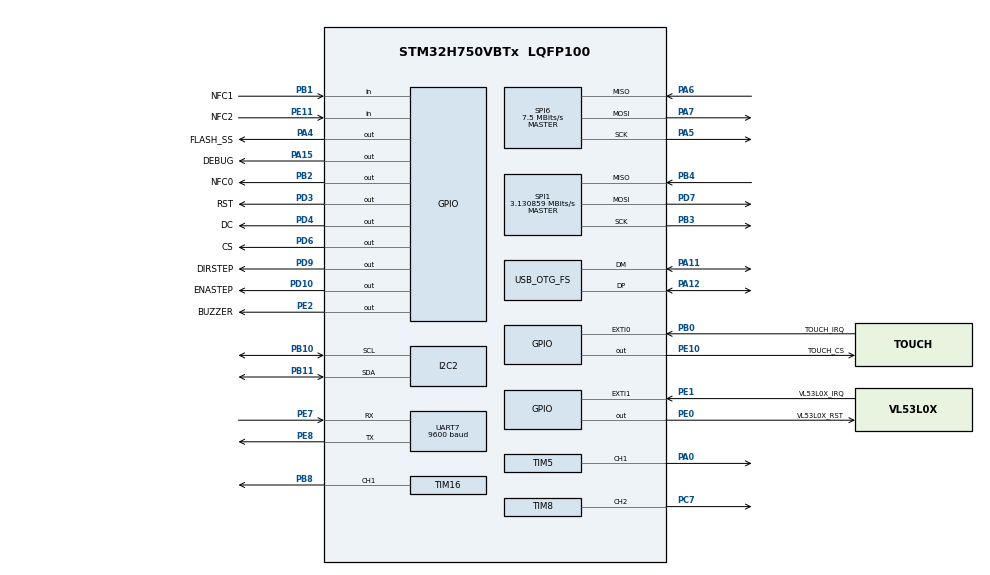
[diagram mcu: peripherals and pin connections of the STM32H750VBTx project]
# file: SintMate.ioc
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Dma.Request0=TIM16_CH1
Dma.Request1=SPI1_TX
Dma.Request2=TIM8_CH2
Dma.SPI1_TX.1.Direction=DMA_MEMORY_TO_PERIPH
Dma.SPI1_TX.1.EventEnable=DISABLE
Dma.SPI1_TX.1.FIFOMode=DMA_FIFOMODE_DISABLE
Dma.SPI1_TX.1.Instance=DMA1_Stream0
Dma.SPI1_TX.1.MemDataAlignment=DMA_MDATAALIGN_BYTE
Dma.SPI1_TX.1.MemInc=DMA_MINC_ENABLE
Dma.SPI1_TX.1.Mode=DMA_NORMAL
Dma.SPI1_TX.1.PeriphDataAlignment=DMA_PDATAALIGN_BYTE
Dma.SPI1_TX.1.PeriphInc=DMA_PINC_DISABLE
Dma.SPI1_TX.1.Polarity=HAL_DMAMUX_REQ_GEN_RISING
Dma.SPI1_TX.1.Priority=DMA_PRIORITY_LOW
Dma.SPI1_TX.1.RequestNumber=1
Dma.SPI1_TX.1.SignalID=NONE
Dma.SPI1_TX.1.SyncEnable=DISABLE
Dma.SPI1_TX.1.SyncPolarity=HAL_DMAMUX_SYNC_NO_EVENT
Dma.SPI1_TX.1.SyncRequestNumber=1
Dma.SPI1_TX.1.SyncSignalID=NONE
Dma.TIM16_CH1.0.Direction=DMA_MEMORY_TO_PERIPH
Dma.TIM16_CH1.0.EventEnable=DISABLE
Dma.TIM16_CH1.0.FIFOMode=DMA_FIFOMODE_DISABLE
Dma.TIM16_CH1.0.Instance=DMA1_Stream1
Dma.TIM16_CH1.0.MemDataAlignment=DMA_MDATAALIGN_HALFWORD
Dma.TIM16_CH1.0.MemInc=DMA_MINC_ENABLE
Dma.TIM16_CH1.0.Mode=DMA_NORMAL
Dma.TIM16_CH1.0.PeriphDataAlignment=DMA_PDATAALIGN_HALFWORD
Dma.TIM16_CH1.0.PeriphInc=DMA_PINC_DISABLE
Dma.TIM16_CH1.0.Polarity=HAL_DMAMUX_REQ_GEN_RISING
Dma.TIM16_CH1.0.Priority=DMA_PRIORITY_LOW
Dma.TIM16_CH1.0.RequestNumber=1
Dma.TIM16_CH1.0.SignalID=NONE
Dma.TIM16_CH1.0.SyncEnable=DISABLE
Dma.TIM16_CH1.0.SyncPolarity=HAL_DMAMUX_SYNC_NO_EVENT
Dma.TIM16_CH1.0.SyncRequestNumber=1
Dma.TIM16_CH1.0.SyncSignalID=NONE
Dma.TIM8_CH2.2.Direction=DMA_MEMORY_TO_PERIPH
Dma.TIM8_CH2.2.EventEnable=DISABLE
Dma.TIM8_CH2.2.FIFOMode=DMA_FIFOMODE_DISABLE
Dma.TIM8_CH2.2.Instance=DMA1_Stream2
Dma.TIM8_CH2.2.MemDataAlignment=DMA_MDATAALIGN_HALFWORD
Dma.TIM8_CH2.2.MemInc=DMA_MINC_ENABLE
Dma.TIM8_CH2.2.Mode=DMA_NORMAL
Dma.TIM8_CH2.2.PeriphDataAlignment=DMA_PDATAALIGN_HALFWORD
Dma.TIM8_CH2.2.PeriphInc=DMA_PINC_DISABLE
Dma.TIM8_CH2.2.Polarity=HAL_DMAMUX_REQ_GEN_RISING
Dma.TIM8_CH2.2.Priority=DMA_PRIORITY_LOW
Dma.TIM8_CH2.2.RequestNumber=1
Dma.TIM8_CH2.2.SignalID=NONE
Dma.TIM8_CH2.2.SyncEnable=DISABLE
Dma.TIM8_CH2.2.SyncPolarity=HAL_DMAMUX_SYNC_NO_EVENT
Dma.TIM8_CH2.2.SyncRequestNumber=1
Dma.TIM8_CH2.2.SyncSignalID=NONE
I2C2.Speed=100
I2C2.Timing=0x00000E14
Mcu.Family=STM32H7
Mcu.Name=STM32H750VBTx
Mcu.Package=LQFP100
NVIC.DMA1_Stream0_IRQn=true\:0\:0\:false\:false\:true\:false\:true
NVIC.DMA1_Stream1_IRQn=true\:0\:0\:false\:false\:true\:false\:true
NVIC.DMA1_Stream2_IRQn=true\:0\:0\:false\:false\:true\:false\:true
NVIC.EXTI0_IRQn=true\:0\:0\:false\:false\:true\:true\:true
NVIC.EXTI1_IRQn=true\:0\:0\:false\:false\:true\:true\:true
NVIC.OTG_FS_IRQn=true\:0\:0\:false\:false\:true\:false\:true
NVIC.PriorityGroup=NVIC_PRIORITYGROUP_4
NVIC.SPI1_IRQn=true\:0\:0\:false\:false\:true\:true\:true
NVIC.TIM6_DAC_IRQn=true\:0\:0\:false\:false\:true\:true\:true
NVIC.TIM7_IRQn=true\:0\:0\:false\:false\:true\:true\:true
NVIC.UART7_IRQn=true\:0\:0\:false\:false\:true\:true\:true
PA0.Signal=S_TIM5_CH1
PA11.Mode=Device_Only
PA11.Signal=USB_OTG_FS_DM
PA12.Mode=Device_Only
PA12.Signal=USB_OTG_FS_DP
PA13\ (JTMS/SWDIO).Mode=Serial_Wire
PA13\ (JTMS/SWDIO).Signal=DEBUG_JTMS-SWDIO
PA14\ (JTCK/SWCLK).Mode=Serial_Wire
PA14\ (JTCK/SWCLK).Signal=DEBUG_JTCK-SWCLK
PA15\ (JTDI).GPIO_Label=DEBUG
PA15\ (JTDI).Signal=GPIO_Output
PA4.GPIO_Label=FLASH_SS
PA4.PinState=GPIO_PIN_SET
PA4.Signal=GPIO_Output
PA5.Mode=Full_Duplex_Master
PA5.Signal=SPI6_SCK
PA6.Mode=Full_Duplex_Master
PA6.Signal=SPI6_MISO
PA7.Mode=Full_Duplex_Master
PA7.Signal=SPI6_MOSI
PB0.GPIO_Label=TOUCH_IRQ
PB0.GPIO_ModeDefaultEXTI=GPIO_MODE_IT_FALLING
PB0.GPIO_PuPd=GPIO_PULLUP
PB0.Signal=GPXTI0
PB1.GPIO_Label=NFC1
PB1.GPIO_PuPd=GPIO_PULLUP
PB1.Signal=GPIO_Input
PB10.Mode=I2C
PB10.Signal=I2C2_SCL
PB11.Mode=I2C
PB11.Signal=I2C2_SDA
PB2.GPIO_Label=NFC0
PB2.Signal=GPIO_Output
PB3\ (JTDO/TRACESWO).Mode=Full_Duplex_Master
PB3\ (JTDO/TRACESWO).Signal=SPI1_SCK
PB4\ (NJTRST).Mode=Full_Duplex_Master
PB4\ (NJTRST).Signal=SPI1_MISO
PB8.Signal=S_TIM16_CH1
PC7.Signal=S_TIM8_CH2
PD10.GPIO_Label=ENASTEP
PD10.GPIO_ModeDefaultOutputPP=GPIO_MODE_OUTPUT_OD
PD10.GPIO_PuPd=GPIO_PULLUP
PD10.PinState=GPIO_PIN_SET
PD10.Signal=GPIO_Output
PD3.GPIO_Label=RST
PD3.Signal=GPIO_Output
PD4.GPIO_Label=DC
PD4.Signal=GPIO_Output
PD6.GPIO_Label=CS
PD6.PinState=GPIO_PIN_SET
PD6.Signal=GPIO_Output
PD7.Mode=Full_Duplex_Master
PD7.Signal=SPI1_MOSI
PD9.GPIO_Label=DIRSTEP
PD9.Signal=GPIO_Output
PE0.GPIO_Label=VL53L0X_RST
PE0.Signal=GPIO_Output
PE1.GPIO_Label=VL53L0X_IRQ
PE1.GPIO_ModeDefaultEXTI=GPIO_MODE_IT_FALLING
PE1.GPIO_PuPd=GPIO_PULLUP
PE1.Signal=GPXTI1
PE10.GPIO_Label=TOUCH_CS
PE10.PinState=GPIO_PIN_SET
PE10.Signal=GPIO_Output
PE11.GPIO_Label=NFC2
PE11.GPIO_PuPd=GPIO_PULLUP
PE11.Signal=GPIO_Input
PE2.GPIO_Label=BUZZER
PE2.PinState=GPIO_PIN_SET
PE2.Signal=GPIO_Output
PE7.Mode=Asynchronous
PE7.Signal=UART7_RX
PE8.Mode=Asynchronous
PE8.Signal=UART7_TX
ProjectManager.HeapSize=0x200
ProjectManager.StackSize=0x400
ProjectManager.TargetToolchain=STM32CubeIDE
RCC.ADCFreq_Value=200375000
RCC.APB1Freq_Value=120000000
RCC.APB2Freq_Value=120000000
RCC.APB3Freq_Value=120000000
RCC.APB4Freq_Value=120000000
RCC.CortexFreq_Value=480000000
RCC.D1PPRE=RCC_APB3_DIV2
RCC.D2PPRE1=RCC_APB1_DIV2
RCC.D2PPRE2=RCC_APB2_DIV2
RCC.D3PPRE=RCC_APB4_DIV2
RCC.DIVM1=4
RCC.DIVN1=60
RCC.DIVN2=200
RCC.DIVN3=96
RCC.DIVP3=4
RCC.DIVQ3=4
RCC.DIVR3=1
RCC.HCLKFreq_Value=240000000
RCC.HPRE=RCC_HCLK_DIV2
RCC.HSE_VALUE=24000000
RCC.I2C123CLockSelection=RCC_I2C123CLKSOURCE_CSI
RCC.PLL2FRACN=3072
RCC.PLL3FRACN=3072
RCC.PLLFRACN=0
RCC.SPI123CLockSelection=RCC_SPI123CLKSOURCE_PLL2
RCC.SYSCLKFreq_VALUE=480000000
RCC.SYSCLKSource=RCC_SYSCLKSOURCE_PLLCLK
RCC.USBCLockSelection=RCC_USBCLKSOURCE_HSI48
RCC.USBFreq_Value=48000000
SH.S_TIM16_CH1.0=TIM16_CH1,Output Compare1 CH1
SH.S_TIM5_CH1.0=TIM5_CH1,PWM Generation1 CH1
SH.S_TIM8_CH2.0=TIM8_CH2,PWM Generation2 CH2
SPI1.BaudRatePrescaler=SPI_BAUDRATEPRESCALER_64
SPI1.CalculateBaudRate=3.130859 MBits/s
SPI1.DataSize=SPI_DATASIZE_8BIT
SPI1.Direction=SPI_DIRECTION_2LINES
SPI1.Mode=SPI_MODE_MASTER
SPI1.VirtualType=VM_MASTER
SPI6.BaudRatePrescaler=SPI_BAUDRATEPRESCALER_16
SPI6.CalculateBaudRate=7.5 MBits/s
SPI6.DataSize=SPI_DATASIZE_8BIT
SPI6.Direction=SPI_DIRECTION_2LINES
SPI6.Mode=SPI_MODE_MASTER
SPI6.VirtualType=VM_MASTER
TIM16.AutoReloadPreload=TIM_AUTORELOAD_PRELOAD_ENABLE
TIM16.Channel=TIM_CHANNEL_1
TIM16.OCMode_1=TIM_OCMODE_TOGGLE
TIM16.Period=2002
TIM16.Prescaler=424
TIM16.Pulse=200
TIM5.Channel-PWM\ Generation1\ CH1=TIM_CHANNEL_1
TIM5.Period=1000
TIM5.Prescaler=240
TIM5.Pulse-PWM\ Generation1\ CH1=500
TIM6.Period=1587
TIM6.Prescaler=2400
TIM7.Period=10000
TIM7.Prescaler=2400
TIM8.AutoReloadPreload=TIM_AUTORELOAD_PRELOAD_ENABLE
TIM8.Channel-PWM\ Generation2\ CH2=TIM_CHANNEL_2
TIM8.Period=90
TIM8.Prescaler=1
UART7.BaudRate=9600
USB_DEVICE.CLASS_NAME_FS=CDC
USB_DEVICE.VirtualMode-CDC_FS=Cdc
USB_DEVICE.VirtualModeFS=Cdc_FS
USB_OTG_FS.VirtualMode=Device_Only
VP_TIM16_VS_ClockSourceINT.Mode=Enable_Timer
VP_TIM6_VS_ClockSourceINT.Mode=Enable_Timer
VP_TIM7_VS_ClockSourceINT.Mode=Enable_Timer
VP_USB_DEVICE_VS_USB_DEVICE_CDC_FS.Mode=CDC_FS
board=custom

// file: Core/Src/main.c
/* USER CODE BEGIN Header */
/**
  ******************************************************************************
  * @file           : main.c
  * @brief          : Main program body
  ******************************************************************************
  * @attention
  *
  * <h2><center>&copy; Copyright (c) 2021 STMicroelectronics.
  * All rights reserved.</center></h2>
  *
  * This software component is licensed by ST under BSD 3-Clause license,
  * the "License"; You may not use this file except in compliance with the
  * License. You may obtain a copy of the License at:
  *                        opensource.org/licenses/BSD-3-Clause
  *
  ******************************************************************************
  */
/* USER CODE END Header */
#include "main.h"
#include "usb_device.h"

I2C_HandleTypeDef hi2c2;

SPI_HandleTypeDef hspi1;
SPI_HandleTypeDef hspi6;
DMA_HandleTypeDef hdma_spi1_tx;

TIM_HandleTypeDef htim5;
TIM_HandleTypeDef htim6;
TIM_HandleTypeDef htim7;
TIM_HandleTypeDef htim8;
TIM_HandleTypeDef htim16;
DMA_HandleTypeDef hdma_tim8_ch2;
DMA_HandleTypeDef hdma_tim16_ch1;

UART_HandleTypeDef huart7;

void SystemClock_Config(void);
static void MX_GPIO_Init(void);
static void MX_DMA_Init(void);
static void MX_TIM16_Init(void);
static void MX_I2C2_Init(void);
static void MX_SPI1_Init(void);
static void MX_SPI6_Init(void);
static void MX_TIM5_Init(void);
static void MX_TIM7_Init(void);
static void MX_TIM8_Init(void);
static void MX_UART7_Init(void);
static void MX_TIM6_Init(void);

int main(void)
{

  /* MCU Configuration--------------------------------------------------------*/

  /* Reset of all peripherals, Initializes the Flash interface and the Systick. */
  HAL_Init();

  /* Configure the system clock */
  SystemClock_Config();

  /* Initialize all configured peripherals */
  MX_GPIO_Init();
  MX_DMA_Init();
  MX_TIM16_Init();
  MX_I2C2_Init();
  MX_SPI1_Init();
  MX_SPI6_Init();
  MX_TIM5_Init();
  MX_TIM7_Init();
  MX_USB_DEVICE_Init();
  MX_TIM8_Init();
  MX_UART7_Init();
  MX_TIM6_Init();
  /* USER CODE BEGIN 2 */
  Init_SintMate();

  /* USER CODE END 2 */

  /* Infinite loop */
  /* USER CODE BEGIN WHILE */
  while (1)
  {
	  SintMateLoop();

    /* USER CODE END WHILE */

  }
}

void SystemClock_Config(void)
{
  RCC_OscInitTypeDef RCC_OscInitStruct = {0};
  RCC_ClkInitTypeDef RCC_ClkInitStruct = {0};
  RCC_PeriphCLKInitTypeDef PeriphClkInitStruct = {0};

  /** Supply configuration update enable
  */
  HAL_PWREx_ConfigSupply(PWR_LDO_SUPPLY);
  /** Configure the main internal regulator output voltage
  */
  __HAL_PWR_VOLTAGESCALING_CONFIG(PWR_REGULATOR_VOLTAGE_SCALE0);

  while(!__HAL_PWR_GET_FLAG(PWR_FLAG_VOSRDY)) {}
  /** Macro to configure the PLL clock source
  */
  __HAL_RCC_PLL_PLLSOURCE_CONFIG(RCC_PLLSOURCE_HSI);
  /** Initializes the RCC Oscillators according to the specified parameters
  * in the RCC_OscInitTypeDef structure.
  */
  RCC_OscInitStruct.OscillatorType = RCC_OSCILLATORTYPE_HSI48|RCC_OSCILLATORTYPE_CSI
                              |RCC_OSCILLATORTYPE_HSI;
  RCC_OscInitStruct.HSIState = RCC_HSI_DIV1;
  RCC_OscInitStruct.HSICalibrationValue = RCC_HSICALIBRATION_DEFAULT;
  RCC_OscInitStruct.HSI48State = RCC_HSI48_ON;
  RCC_OscInitStruct.CSIState = RCC_CSI_ON;
  RCC_OscInitStruct.CSICalibrationValue = 16;
  RCC_OscInitStruct.PLL.PLLState = RCC_PLL_ON;
  RCC_OscInitStruct.PLL.PLLSource = RCC_PLLSOURCE_HSI;
  RCC_OscInitStruct.PLL.PLLM = 4;
  RCC_OscInitStruct.PLL.PLLN = 60;
  RCC_OscInitStruct.PLL.PLLP = 2;
  RCC_OscInitStruct.PLL.PLLQ = 2;
  RCC_OscInitStruct.PLL.PLLR = 2;
  RCC_OscInitStruct.PLL.PLLRGE = RCC_PLL1VCIRANGE_3;
  RCC_OscInitStruct.PLL.PLLVCOSEL = RCC_PLL1VCOWIDE;
  RCC_OscInitStruct.PLL.PLLFRACN = 0;
  if (HAL_RCC_OscConfig(&RCC_OscInitStruct) != HAL_OK)
  {
    Error_Handler();
  }
  /** Initializes the CPU, AHB and APB buses clocks
  */
  RCC_ClkInitStruct.ClockType = RCC_CLOCKTYPE_HCLK|RCC_CLOCKTYPE_SYSCLK
                              |RCC_CLOCKTYPE_PCLK1|RCC_CLOCKTYPE_PCLK2
                              |RCC_CLOCKTYPE_D3PCLK1|RCC_CLOCKTYPE_D1PCLK1;
  RCC_ClkInitStruct.SYSCLKSource = RCC_SYSCLKSOURCE_PLLCLK;
  RCC_ClkInitStruct.SYSCLKDivider = RCC_SYSCLK_DIV1;
  RCC_ClkInitStruct.AHBCLKDivider = RCC_HCLK_DIV2;
  RCC_ClkInitStruct.APB3CLKDivider = RCC_APB3_DIV2;
  RCC_ClkInitStruct.APB1CLKDivider = RCC_APB1_DIV2;
  RCC_ClkInitStruct.APB2CLKDivider = RCC_APB2_DIV2;
  RCC_ClkInitStruct.APB4CLKDivider = RCC_APB4_DIV2;

  if (HAL_RCC_ClockConfig(&RCC_ClkInitStruct, FLASH_LATENCY_4) != HAL_OK)
  {
    Error_Handler();
  }
  PeriphClkInitStruct.PeriphClockSelection = RCC_PERIPHCLK_UART7|RCC_PERIPHCLK_SPI1
                              |RCC_PERIPHCLK_I2C2|RCC_PERIPHCLK_SPI6
                              |RCC_PERIPHCLK_USB;
  PeriphClkInitStruct.PLL2.PLL2M = 32;
  PeriphClkInitStruct.PLL2.PLL2N = 200;
  PeriphClkInitStruct.PLL2.PLL2P = 2;
  PeriphClkInitStruct.PLL2.PLL2Q = 2;
  PeriphClkInitStruct.PLL2.PLL2R = 2;
  PeriphClkInitStruct.PLL2.PLL2RGE = RCC_PLL2VCIRANGE_1;
  PeriphClkInitStruct.PLL2.PLL2VCOSEL = RCC_PLL2VCOWIDE;
  PeriphClkInitStruct.PLL2.PLL2FRACN = 3072;
  PeriphClkInitStruct.Spi123ClockSelection = RCC_SPI123CLKSOURCE_PLL2;
  PeriphClkInitStruct.Usart234578ClockSelection = RCC_USART234578CLKSOURCE_D2PCLK1;
  PeriphClkInitStruct.I2c123ClockSelection = RCC_I2C123CLKSOURCE_CSI;
  PeriphClkInitStruct.UsbClockSelection = RCC_USBCLKSOURCE_HSI48;
  PeriphClkInitStruct.Spi6ClockSelection = RCC_SPI6CLKSOURCE_D3PCLK1;
  if (HAL_RCCEx_PeriphCLKConfig(&PeriphClkInitStruct) != HAL_OK)
  {
    Error_Handler();
  }
  /** Enable USB Voltage detector
  */
  HAL_PWREx_EnableUSBVoltageDetector();
}

static void MX_I2C2_Init(void)
{

  hi2c2.Instance = I2C2;
  hi2c2.Init.Timing = 0x00000E14;
  hi2c2.Init.OwnAddress1 = 0;
  hi2c2.Init.AddressingMode = I2C_ADDRESSINGMODE_7BIT;
  hi2c2.Init.DualAddressMode = I2C_DUALADDRESS_DISABLE;
  hi2c2.Init.OwnAddress2 = 0;
  hi2c2.Init.OwnAddress2Masks = I2C_OA2_NOMASK;
  hi2c2.Init.GeneralCallMode = I2C_GENERALCALL_DISABLE;
  hi2c2.Init.NoStretchMode = I2C_NOSTRETCH_DISABLE;
  if (HAL_I2C_Init(&hi2c2) != HAL_OK)
  {
    Error_Handler();
  }
  /** Configure Analogue filter
  */
  if (HAL_I2CEx_ConfigAnalogFilter(&hi2c2, I2C_ANALOGFILTER_ENABLE) != HAL_OK)
  {
    Error_Handler();
  }
  /** Configure Digital filter
  */
  if (HAL_I2CEx_ConfigDigitalFilter(&hi2c2, 0) != HAL_OK)
  {
    Error_Handler();
  }

}

static void MX_SPI1_Init(void)
{

  /* SPI1 parameter configuration*/
  hspi1.Instance = SPI1;
  hspi1.Init.Mode = SPI_MODE_MASTER;
  hspi1.Init.Direction = SPI_DIRECTION_2LINES;
  hspi1.Init.DataSize = SPI_DATASIZE_8BIT;
  hspi1.Init.CLKPolarity = SPI_POLARITY_LOW;
  hspi1.Init.CLKPhase = SPI_PHASE_1EDGE;
  hspi1.Init.NSS = SPI_NSS_SOFT;
  hspi1.Init.BaudRatePrescaler = SPI_BAUDRATEPRESCALER_64;
  hspi1.Init.FirstBit = SPI_FIRSTBIT_MSB;
  hspi1.Init.TIMode = SPI_TIMODE_DISABLE;
  hspi1.Init.CRCCalculation = SPI_CRCCALCULATION_DISABLE;
  hspi1.Init.CRCPolynomial = 0x0;
  hspi1.Init.NSSPMode = SPI_NSS_PULSE_ENABLE;
  hspi1.Init.NSSPolarity = SPI_NSS_POLARITY_LOW;
  hspi1.Init.FifoThreshold = SPI_FIFO_THRESHOLD_01DATA;
  hspi1.Init.TxCRCInitializationPattern = SPI_CRC_INITIALIZATION_ALL_ZERO_PATTERN;
  hspi1.Init.RxCRCInitializationPattern = SPI_CRC_INITIALIZATION_ALL_ZERO_PATTERN;
  hspi1.Init.MasterSSIdleness = SPI_MASTER_SS_IDLENESS_00CYCLE;
  hspi1.Init.MasterInterDataIdleness = SPI_MASTER_INTERDATA_IDLENESS_00CYCLE;
  hspi1.Init.MasterReceiverAutoSusp = SPI_MASTER_RX_AUTOSUSP_DISABLE;
  hspi1.Init.MasterKeepIOState = SPI_MASTER_KEEP_IO_STATE_DISABLE;
  hspi1.Init.IOSwap = SPI_IO_SWAP_DISABLE;
  if (HAL_SPI_Init(&hspi1) != HAL_OK)
  {
    Error_Handler();
  }

}

static void MX_SPI6_Init(void)
{

  /* SPI6 parameter configuration*/
  hspi6.Instance = SPI6;
  hspi6.Init.Mode = SPI_MODE_MASTER;
  hspi6.Init.Direction = SPI_DIRECTION_2LINES;
  hspi6.Init.DataSize = SPI_DATASIZE_8BIT;
  hspi6.Init.CLKPolarity = SPI_POLARITY_LOW;
  hspi6.Init.CLKPhase = SPI_PHASE_1EDGE;
  hspi6.Init.NSS = SPI_NSS_SOFT;
  hspi6.Init.BaudRatePrescaler = SPI_BAUDRATEPRESCALER_16;
  hspi6.Init.FirstBit = SPI_FIRSTBIT_MSB;
  hspi6.Init.TIMode = SPI_TIMODE_DISABLE;
  hspi6.Init.CRCCalculation = SPI_CRCCALCULATION_DISABLE;
  hspi6.Init.CRCPolynomial = 0x0;
  hspi6.Init.NSSPMode = SPI_NSS_PULSE_ENABLE;
  hspi6.Init.NSSPolarity = SPI_NSS_POLARITY_LOW;
  hspi6.Init.FifoThreshold = SPI_FIFO_THRESHOLD_01DATA;
  hspi6.Init.TxCRCInitializationPattern = SPI_CRC_INITIALIZATION_ALL_ZERO_PATTERN;
  hspi6.Init.RxCRCInitializationPattern = SPI_CRC_INITIALIZATION_ALL_ZERO_PATTERN;
  hspi6.Init.MasterSSIdleness = SPI_MASTER_SS_IDLENESS_00CYCLE;
  hspi6.Init.MasterInterDataIdleness = SPI_MASTER_INTERDATA_IDLENESS_00CYCLE;
  hspi6.Init.MasterReceiverAutoSusp = SPI_MASTER_RX_AUTOSUSP_DISABLE;
  hspi6.Init.MasterKeepIOState = SPI_MASTER_KEEP_IO_STATE_DISABLE;
  hspi6.Init.IOSwap = SPI_IO_SWAP_DISABLE;
  if (HAL_SPI_Init(&hspi6) != HAL_OK)
  {
    Error_Handler();
  }

}

static void MX_TIM5_Init(void)
{

  TIM_MasterConfigTypeDef sMasterConfig = {0};
  TIM_OC_InitTypeDef sConfigOC = {0};

  htim5.Instance = TIM5;
  htim5.Init.Prescaler = 240;
  htim5.Init.CounterMode = TIM_COUNTERMODE_UP;
  htim5.Init.Period = 1000;
  htim5.Init.ClockDivision = TIM_CLOCKDIVISION_DIV1;
  htim5.Init.AutoReloadPreload = TIM_AUTORELOAD_PRELOAD_DISABLE;
  if (HAL_TIM_PWM_Init(&htim5) != HAL_OK)
  {
    Error_Handler();
  }
  sMasterConfig.MasterOutputTrigger = TIM_TRGO_RESET;
  sMasterConfig.MasterSlaveMode = TIM_MASTERSLAVEMODE_DISABLE;
  if (HAL_TIMEx_MasterConfigSynchronization(&htim5, &sMasterConfig) != HAL_OK)
  {
    Error_Handler();
  }
  sConfigOC.OCMode = TIM_OCMODE_PWM1;
  sConfigOC.Pulse = 500;
  sConfigOC.OCPolarity = TIM_OCPOLARITY_HIGH;
  sConfigOC.OCFastMode = TIM_OCFAST_DISABLE;
  if (HAL_TIM_PWM_ConfigChannel(&htim5, &sConfigOC, TIM_CHANNEL_1) != HAL_OK)
  {
    Error_Handler();
  }
  HAL_TIM_MspPostInit(&htim5);

}

static void MX_TIM6_Init(void)
{

  TIM_MasterConfigTypeDef sMasterConfig = {0};

  htim6.Instance = TIM6;
  htim6.Init.Prescaler = 2400;
  htim6.Init.CounterMode = TIM_COUNTERMODE_UP;
  htim6.Init.Period = 1587;
  htim6.Init.AutoReloadPreload = TIM_AUTORELOAD_PRELOAD_DISABLE;
  if (HAL_TIM_Base_Init(&htim6) != HAL_OK)
  {
    Error_Handler();
  }
  sMasterConfig.MasterOutputTrigger = TIM_TRGO_RESET;
  sMasterConfig.MasterSlaveMode = TIM_MASTERSLAVEMODE_DISABLE;
  if (HAL_TIMEx_MasterConfigSynchronization(&htim6, &sMasterConfig) != HAL_OK)
  {
    Error_Handler();
  }

}

static void MX_TIM7_Init(void)
{

  TIM_MasterConfigTypeDef sMasterConfig = {0};

  htim7.Instance = TIM7;
  htim7.Init.Prescaler = 2400;
  htim7.Init.CounterMode = TIM_COUNTERMODE_UP;
  htim7.Init.Period = 10000;
  htim7.Init.AutoReloadPreload = TIM_AUTORELOAD_PRELOAD_DISABLE;
  if (HAL_TIM_Base_Init(&htim7) != HAL_OK)
  {
    Error_Handler();
  }
  sMasterConfig.MasterOutputTrigger = TIM_TRGO_RESET;
  sMasterConfig.MasterSlaveMode = TIM_MASTERSLAVEMODE_DISABLE;
  if (HAL_TIMEx_MasterConfigSynchronization(&htim7, &sMasterConfig) != HAL_OK)
  {
    Error_Handler();
  }

}

static void MX_TIM8_Init(void)
{

  TIM_MasterConfigTypeDef sMasterConfig = {0};
  TIM_OC_InitTypeDef sConfigOC = {0};
  TIM_BreakDeadTimeConfigTypeDef sBreakDeadTimeConfig = {0};

  htim8.Instance = TIM8;
  htim8.Init.Prescaler = 1;
  htim8.Init.CounterMode = TIM_COUNTERMODE_UP;
  htim8.Init.Period = 90;
  htim8.Init.ClockDivision = TIM_CLOCKDIVISION_DIV1;
  htim8.Init.RepetitionCounter = 0;
  htim8.Init.AutoReloadPreload = TIM_AUTORELOAD_PRELOAD_ENABLE;
  if (HAL_TIM_PWM_Init(&htim8) != HAL_OK)
  {
    Error_Handler();
  }
  sMasterConfig.MasterOutputTrigger = TIM_TRGO_RESET;
  sMasterConfig.MasterOutputTrigger2 = TIM_TRGO2_RESET;
  sMasterConfig.MasterSlaveMode = TIM_MASTERSLAVEMODE_DISABLE;
  if (HAL_TIMEx_MasterConfigSynchronization(&htim8, &sMasterConfig) != HAL_OK)
  {
    Error_Handler();
  }
  sConfigOC.OCMode = TIM_OCMODE_PWM1;
  sConfigOC.Pulse = 0;
  sConfigOC.OCPolarity = TIM_OCPOLARITY_HIGH;
  sConfigOC.OCNPolarity = TIM_OCNPOLARITY_HIGH;
  sConfigOC.OCFastMode = TIM_OCFAST_DISABLE;
  sConfigOC.OCIdleState = TIM_OCIDLESTATE_RESET;
  sConfigOC.OCNIdleState = TIM_OCNIDLESTATE_RESET;
  if (HAL_TIM_PWM_ConfigChannel(&htim8, &sConfigOC, TIM_CHANNEL_2) != HAL_OK)
  {
    Error_Handler();
  }
  sBreakDeadTimeConfig.OffStateRunMode = TIM_OSSR_DISABLE;
  sBreakDeadTimeConfig.OffStateIDLEMode = TIM_OSSI_DISABLE;
  sBreakDeadTimeConfig.LockLevel = TIM_LOCKLEVEL_OFF;
  sBreakDeadTimeConfig.DeadTime = 0;
  sBreakDeadTimeConfig.BreakState = TIM_BREAK_DISABLE;
  sBreakDeadTimeConfig.BreakPolarity = TIM_BREAKPOLARITY_HIGH;
  sBreakDeadTimeConfig.BreakFilter = 0;
  sBreakDeadTimeConfig.Break2State = TIM_BREAK2_DISABLE;
  sBreakDeadTimeConfig.Break2Polarity = TIM_BREAK2POLARITY_HIGH;
  sBreakDeadTimeConfig.Break2Filter = 0;
  sBreakDeadTimeConfig.AutomaticOutput = TIM_AUTOMATICOUTPUT_DISABLE;
  if (HAL_TIMEx_ConfigBreakDeadTime(&htim8, &sBreakDeadTimeConfig) != HAL_OK)
  {
    Error_Handler();
  }
  HAL_TIM_MspPostInit(&htim8);

}

static void MX_TIM16_Init(void)
{

  TIM_OC_InitTypeDef sConfigOC = {0};
  TIM_BreakDeadTimeConfigTypeDef sBreakDeadTimeConfig = {0};

  htim16.Instance = TIM16;
  htim16.Init.Prescaler = 424;
  htim16.Init.CounterMode = TIM_COUNTERMODE_UP;
  htim16.Init.Period = 2002;
  htim16.Init.ClockDivision = TIM_CLOCKDIVISION_DIV1;
  htim16.Init.RepetitionCounter = 0;
  htim16.Init.AutoReloadPreload = TIM_AUTORELOAD_PRELOAD_ENABLE;
  if (HAL_TIM_Base_Init(&htim16) != HAL_OK)
  {
    Error_Handler();
  }
  if (HAL_TIM_OC_Init(&htim16) != HAL_OK)
  {
    Error_Handler();
  }
  sConfigOC.OCMode = TIM_OCMODE_TOGGLE;
  sConfigOC.Pulse = 200;
  sConfigOC.OCPolarity = TIM_OCPOLARITY_HIGH;
  sConfigOC.OCNPolarity = TIM_OCNPOLARITY_HIGH;
  sConfigOC.OCFastMode = TIM_OCFAST_DISABLE;
  sConfigOC.OCIdleState = TIM_OCIDLESTATE_RESET;
  sConfigOC.OCNIdleState = TIM_OCNIDLESTATE_RESET;
  if (HAL_TIM_OC_ConfigChannel(&htim16, &sConfigOC, TIM_CHANNEL_1) != HAL_OK)
  {
    Error_Handler();
  }
  sBreakDeadTimeConfig.OffStateRunMode = TIM_OSSR_DISABLE;
  sBreakDeadTimeConfig.OffStateIDLEMode = TIM_OSSI_DISABLE;
  sBreakDeadTimeConfig.LockLevel = TIM_LOCKLEVEL_OFF;
  sBreakDeadTimeConfig.DeadTime = 0;
  sBreakDeadTimeConfig.BreakState = TIM_BREAK_DISABLE;
  sBreakDeadTimeConfig.BreakPolarity = TIM_BREAKPOLARITY_HIGH;
  sBreakDeadTimeConfig.BreakFilter = 0;
  sBreakDeadTimeConfig.AutomaticOutput = TIM_AUTOMATICOUTPUT_DISABLE;
  if (HAL_TIMEx_ConfigBreakDeadTime(&htim16, &sBreakDeadTimeConfig) != HAL_OK)
  {
    Error_Handler();
  }
  HAL_TIM_MspPostInit(&htim16);

}

static void MX_UART7_Init(void)
{

  huart7.Instance = UART7;
  huart7.Init.BaudRate = 9600;
  huart7.Init.WordLength = UART_WORDLENGTH_8B;
  huart7.Init.StopBits = UART_STOPBITS_1;
  huart7.Init.Parity = UART_PARITY_NONE;
  huart7.Init.Mode = UART_MODE_TX_RX;
  huart7.Init.HwFlowCtl = UART_HWCONTROL_NONE;
  huart7.Init.OverSampling = UART_OVERSAMPLING_16;
  huart7.Init.OneBitSampling = UART_ONE_BIT_SAMPLE_DISABLE;
  huart7.Init.ClockPrescaler = UART_PRESCALER_DIV1;
  huart7.AdvancedInit.AdvFeatureInit = UART_ADVFEATURE_NO_INIT;
  if (HAL_UART_Init(&huart7) != HAL_OK)
  {
    Error_Handler();
  }
  if (HAL_UARTEx_SetTxFifoThreshold(&huart7, UART_TXFIFO_THRESHOLD_1_8) != HAL_OK)
  {
    Error_Handler();
  }
  if (HAL_UARTEx_SetRxFifoThreshold(&huart7, UART_RXFIFO_THRESHOLD_1_8) != HAL_OK)
  {
    Error_Handler();
  }
  if (HAL_UARTEx_DisableFifoMode(&huart7) != HAL_OK)
  {
    Error_Handler();
  }

}

static void MX_DMA_Init(void)
{

  /* DMA controller clock enable */
  __HAL_RCC_DMA1_CLK_ENABLE();

  /* DMA interrupt init */
  /* DMA1_Stream0_IRQn interrupt configuration */
  HAL_NVIC_SetPriority(DMA1_Stream0_IRQn, 0, 0);
  HAL_NVIC_EnableIRQ(DMA1_Stream0_IRQn);
  /* DMA1_Stream1_IRQn interrupt configuration */
  HAL_NVIC_SetPriority(DMA1_Stream1_IRQn, 0, 0);
  HAL_NVIC_EnableIRQ(DMA1_Stream1_IRQn);
  /* DMA1_Stream2_IRQn interrupt configuration */
  HAL_NVIC_SetPriority(DMA1_Stream2_IRQn, 0, 0);
  HAL_NVIC_EnableIRQ(DMA1_Stream2_IRQn);

}

static void MX_GPIO_Init(void)
{
  GPIO_InitTypeDef GPIO_InitStruct = {0};

  /* GPIO Ports Clock Enable */
  __HAL_RCC_GPIOE_CLK_ENABLE();
  __HAL_RCC_GPIOA_CLK_ENABLE();
  __HAL_RCC_GPIOB_CLK_ENABLE();
  __HAL_RCC_GPIOD_CLK_ENABLE();
  __HAL_RCC_GPIOC_CLK_ENABLE();

  /*Configure GPIO pin Output Level */
  HAL_GPIO_WritePin(GPIOE, BUZZER_Pin|TOUCH_CS_Pin, GPIO_PIN_SET);

  /*Configure GPIO pin Output Level */
  HAL_GPIO_WritePin(FLASH_SS_GPIO_Port, FLASH_SS_Pin, GPIO_PIN_SET);

  /*Configure GPIO pin Output Level */
  HAL_GPIO_WritePin(NFC0_GPIO_Port, NFC0_Pin, GPIO_PIN_RESET);

  /*Configure GPIO pin Output Level */
  HAL_GPIO_WritePin(GPIOD, DIRSTEP_Pin|RST_Pin|DC_Pin, GPIO_PIN_RESET);

  /*Configure GPIO pin Output Level */
  HAL_GPIO_WritePin(GPIOD, ENASTEP_Pin|CS_Pin, GPIO_PIN_SET);

  /*Configure GPIO pin Output Level */
  HAL_GPIO_WritePin(DEBUG_GPIO_Port, DEBUG_Pin, GPIO_PIN_RESET);

  /*Configure GPIO pin Output Level */
  HAL_GPIO_WritePin(VL53L0X_RST_GPIO_Port, VL53L0X_RST_Pin, GPIO_PIN_RESET);

  /*Configure GPIO pins : BUZZER_Pin TOUCH_CS_Pin VL53L0X_RST_Pin */
  GPIO_InitStruct.Pin = BUZZER_Pin|TOUCH_CS_Pin|VL53L0X_RST_Pin;
  GPIO_InitStruct.Mode = GPIO_MODE_OUTPUT_PP;
  GPIO_InitStruct.Pull = GPIO_NOPULL;
  GPIO_InitStruct.Speed = GPIO_SPEED_FREQ_LOW;
  HAL_GPIO_Init(GPIOE, &GPIO_InitStruct);

  /*Configure GPIO pins : FLASH_SS_Pin DEBUG_Pin */
  GPIO_InitStruct.Pin = FLASH_SS_Pin|DEBUG_Pin;
  GPIO_InitStruct.Mode = GPIO_MODE_OUTPUT_PP;
  GPIO_InitStruct.Pull = GPIO_NOPULL;
  GPIO_InitStruct.Speed = GPIO_SPEED_FREQ_LOW;
  HAL_GPIO_Init(GPIOA, &GPIO_InitStruct);

  /*Configure GPIO pin : TOUCH_IRQ_Pin */
  GPIO_InitStruct.Pin = TOUCH_IRQ_Pin;
  GPIO_InitStruct.Mode = GPIO_MODE_IT_FALLING;
  GPIO_InitStruct.Pull = GPIO_PULLUP;
  HAL_GPIO_Init(TOUCH_IRQ_GPIO_Port, &GPIO_InitStruct);

  /*Configure GPIO pin : NFC1_Pin */
  GPIO_InitStruct.Pin = NFC1_Pin;
  GPIO_InitStruct.Mode = GPIO_MODE_INPUT;
  GPIO_InitStruct.Pull = GPIO_PULLUP;
  HAL_GPIO_Init(NFC1_GPIO_Port, &GPIO_InitStruct);

  /*Configure GPIO pin : NFC0_Pin */
  GPIO_InitStruct.Pin = NFC0_Pin;
  GPIO_InitStruct.Mode = GPIO_MODE_OUTPUT_PP;
  GPIO_InitStruct.Pull = GPIO_NOPULL;
  GPIO_InitStruct.Speed = GPIO_SPEED_FREQ_LOW;
  HAL_GPIO_Init(NFC0_GPIO_Port, &GPIO_InitStruct);

  /*Configure GPIO pin : NFC2_Pin */
  GPIO_InitStruct.Pin = NFC2_Pin;
  GPIO_InitStruct.Mode = GPIO_MODE_INPUT;
  GPIO_InitStruct.Pull = GPIO_PULLUP;
  HAL_GPIO_Init(NFC2_GPIO_Port, &GPIO_InitStruct);

  /*Configure GPIO pins : DIRSTEP_Pin RST_Pin DC_Pin CS_Pin */
  GPIO_InitStruct.Pin = DIRSTEP_Pin|RST_Pin|DC_Pin|CS_Pin;
  GPIO_InitStruct.Mode = GPIO_MODE_OUTPUT_PP;
  GPIO_InitStruct.Pull = GPIO_NOPULL;
  GPIO_InitStruct.Speed = GPIO_SPEED_FREQ_LOW;
  HAL_GPIO_Init(GPIOD, &GPIO_InitStruct);

  /*Configure GPIO pin : ENASTEP_Pin */
  GPIO_InitStruct.Pin = ENASTEP_Pin;
  GPIO_InitStruct.Mode = GPIO_MODE_OUTPUT_OD;
  GPIO_InitStruct.Pull = GPIO_PULLUP;
  GPIO_InitStruct.Speed = GPIO_SPEED_FREQ_LOW;
  HAL_GPIO_Init(ENASTEP_GPIO_Port, &GPIO_InitStruct);

  /*Configure GPIO pin : VL53L0X_IRQ_Pin */
  GPIO_InitStruct.Pin = VL53L0X_IRQ_Pin;
  GPIO_InitStruct.Mode = GPIO_MODE_IT_FALLING;
  GPIO_InitStruct.Pull = GPIO_PULLUP;
  HAL_GPIO_Init(VL53L0X_IRQ_GPIO_Port, &GPIO_InitStruct);

  /* EXTI interrupt init*/
  HAL_NVIC_SetPriority(EXTI0_IRQn, 0, 0);
  HAL_NVIC_EnableIRQ(EXTI0_IRQn);

  HAL_NVIC_SetPriority(EXTI1_IRQn, 0, 0);
  HAL_NVIC_EnableIRQ(EXTI1_IRQn);

}

void Error_Handler(void)
{
  __disable_irq();
  while (1)
  {
  }
}

/************************ (C) COPYRIGHT STMicroelectronics *****END OF FILE****/
